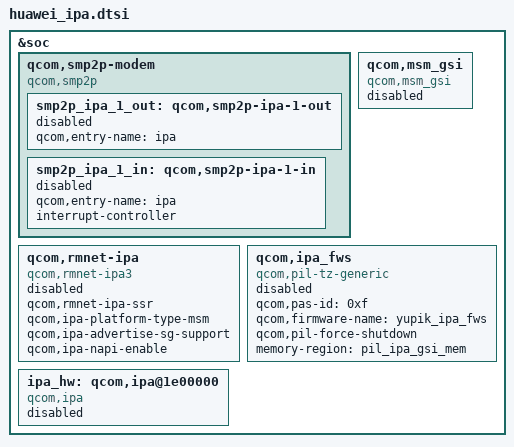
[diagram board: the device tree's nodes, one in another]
&soc{
	qcom,smp2p-modem {
		compatible = "qcom,smp2p";
		smp2p_ipa_1_out: qcom,smp2p-ipa-1-out {
			qcom,entry-name = "ipa";
			#qcom,smem-state-cells = <1>;
			status = "disabled";
		};

		/* ipa - inbound entry from mss */
		smp2p_ipa_1_in: qcom,smp2p-ipa-1-in {
			qcom,entry-name = "ipa";
			interrupt-controller;
			#interrupt-cells = <2>;
			status = "disabled";
		};
	};

	qcom,msm_gsi {
		compatible = "qcom,msm_gsi";
		status = "disabled";
	};

	qcom,rmnet-ipa {
		compatible = "qcom,rmnet-ipa3";
		qcom,rmnet-ipa-ssr;
		qcom,ipa-platform-type-msm;
		qcom,ipa-advertise-sg-support;
		qcom,ipa-napi-enable;
		status = "disabled";
	};

	qcom,ipa_fws {
		compatible = "qcom,pil-tz-generic";
		qcom,pas-id = <0xf>;
		qcom,firmware-name = "yupik_ipa_fws";
		qcom,pil-force-shutdown;
		memory-region = <&pil_ipa_gsi_mem>;
		status = "disabled";
	};

	ipa_hw: qcom,ipa@1e00000 {
		compatible = "qcom,ipa";
		status = "disabled";
	};
};
